# MSPM0G350X register map
Vendor: Texas Instruments; File version: This preliminary header file does not have a version number - build date: 2024-04-29 21:43:54
CPU: CM0 r0p1, little endian, MPU, no FPU, 3 interrupt priority bits
Registers are 32-bit, read-write, reset 0x0 unless marked. A register's access mark holds for its fields unless they carry their own. Offsets are from the block's base; [hi:lo] are bit positions; lines under a group give offsets from that group; {n}, {i} and the like mark numbered series; 'fields as' and 'values as' point back to an identical list; <NAME> marks a mode.

## CANFD0 (part 2 of 3) — PERIPHERALREGION
Base 0x40508000
{0x7200+0xA00*i} CANFD0_TI_WRAPPER[{i}] (i=0..0) group
  {0x0+0x410*j} CANFD0_PROCESSORS[{j}] (j=0..0) group
    {0x0+0x2C*k} CANFD0_MCANSS_REGS[{k}] (k=0..0) group
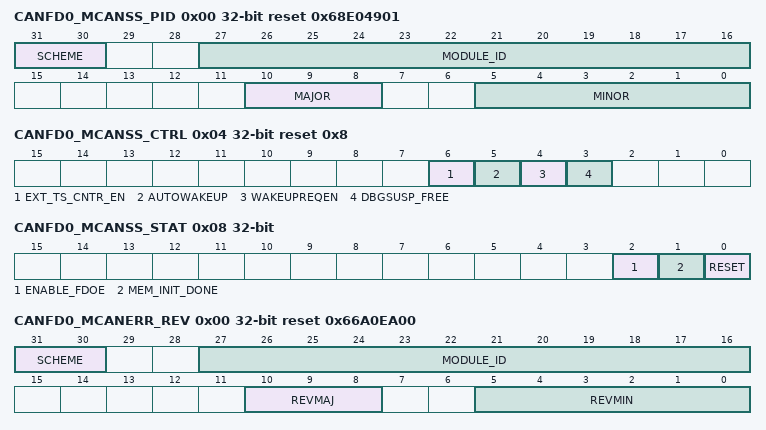
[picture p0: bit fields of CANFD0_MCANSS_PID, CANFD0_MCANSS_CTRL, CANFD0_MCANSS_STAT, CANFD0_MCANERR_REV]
      0x00 CANFD0_MCANSS_PID ro reset 0x68E04901 — MCAN Subsystem Revision Register
        [31:30] SCHEME — PID Register Scheme
        [27:16] MODULE_ID — Module Identification Number
        [10:8] MAJOR — Major Revision of the MCAN Subsystem
        [5:0] MINOR — Minor Revision of the MCAN Subsystem
      0x04 CANFD0_MCANSS_CTRL reset 0x8 — MCAN Subsystem Control Register
        [6] EXT_TS_CNTR_EN — External Timestamp Counter Enable. 0 External timestamp counter disabled 1 External timestamp counter enabled
        [5] AUTOWAKEUP — Automatic Wakeup Enable. Enables the MCANSS to automatically clear the MCAN CCCR.INIT bit, fully waking the MCAN up, on an enabled wakeup request. 0 Disable the automatic write to CCCR.INIT 1 Enable the automatic write to CCCR.INIT
        [4] WAKEUPREQEN — Wakeup Request Enable. Enables the MCANSS to wakeup on CAN RXD activity. 0 Disable wakeup request 1 Enables wakeup request
        [3] DBGSUSP_FREE — Debug Suspend Free Bit. Enables debug suspend. 0 Disable debug suspend 1 Enable debug suspend
      0x08 CANFD0_MCANSS_STAT ro (reset mask 0xFFFFFFFB) — MCAN Subsystem Status Register
        [2] ENABLE_FDOE — Flexible Datarate Operation Enable. Determines whether CAN FD operation may be enabled via the MCAN core CCCR.FDOE bit (bit 8) or if only standard CAN operation is possible with this instance of the MCAN. 0 MCAN is only capable of standard CAN communication 1 MCAN may be configured to perform CAN FD communication
        [1] MEM_INIT_DONE — Memory Initialization Done. 0 Message RAM initialization is in progress 1 Message RAM is initialized for use
        [0] RESET — Soft Reset Status. 0 Not in reset 1 Reset is in progress
      0x0C CANFD0_MCANSS_ICS — MCAN Subsystem Interrupt Clear Shadow Register
        [0] EXT_TS_CNTR_OVFL — External Timestamp Counter Overflow Interrupt Status Clear. Reads always return a 0. 0 Write of '0' has no effect 1 Write of '1' clears the MCANSS_IRS.EXT_TS_CNTR_OVFL bit
      0x10 CANFD0_MCANSS_IRS — MCAN Subsystem Interrupt Raw Satus Register
        [0] EXT_TS_CNTR_OVFL — External Timestamp Counter Overflow Interrupt Status. This bit is set by HW or by a SW write of '1'. To clear, use the MCANSS_ICS.EXT_TS_CNTR_OVFL bit. 0 External timestamp counter has not overflowed 1 External timestamp counter has overflowed When this bit is set to '1' by HW or SW, the MCANSS_EXT_TS_UNSERVICED_INTR_CNTR.EXT_TS_INTR_CNTR bit field will increment by 1.
      0x14 CANFD0_MCANSS_IECS — MCAN Subsystem Interrupt Enable Clear Shadow Register
        [0] EXT_TS_CNTR_OVFL — External Timestamp Counter Overflow Interrupt Enable Clear. Reads always return a 0. 0 Write of '0' has no effect 1 Write of '1' clears the MCANSS_IES.EXT_TS_CNTR_OVFL bit
      0x18 CANFD0_MCANSS_IE — MCAN Subsystem Interrupt Enable Register
        [0] EXT_TS_CNTR_OVFL — External Timestamp Counter Overflow Interrupt Enable. A write of '0' has no effect. A write of '1' sets the MCANSS_IES.EXT_TS_CNTR_OVFL bit.
      0x1C CANFD0_MCANSS_IES ro — MCAN Subsystem Interrupt Enable Status
        [0] EXT_TS_CNTR_OVFL — External Timestamp Counter Overflow Interrupt Enable Status. To set, use the CANSS_IE.EXT_TS_CNTR_OVFL bit. To clear, use the MCANSS_IECS.EXT_TS_CNTR_OVFL bit. 0 External timestamp counter overflow interrupt is not enabled 1 External timestamp counter overflow interrupt is enabled
      0x20 CANFD0_MCANSS_EOI — MCAN Subsystem End of Interrupt
        [7:0] EOI — End of Interrupt. A write to this register will clear the associated interrupt. If the unserviced interrupt counter is > 1, another interrupt is generated. 0x00 External TS Interrupt is cleared 0x01 MCAN(0) interrupt is cleared 0x02 MCAN(1) interrupt is cleared Other writes are ignored.
      0x24 CANFD0_MCANSS_EXT_TS_PRESCALER — MCAN Subsystem External Timestamp Prescaler 0
        [23:0] PRESCALER — External Timestamp Prescaler Reload Value. The external timestamp count rate is the host (system) clock rate divided by this value, except in the case of 0. A zero value in this bit field will act identically to a value of 0x000001.
      0x28 CANFD0_MCANSS_EXT_TS_UNSERVICED_INTR_CNTR ro — MCAN Subsystem External Timestamp Unserviced Interrupts Counter
        [4:0] EXT_TS_INTR_CNTR — External Timestamp Counter Unserviced Rollover Interrupts. If this value is > 1, an MCANSS_EOI write of '1' to bit 0 will issue another interrupt. The status of this bit field is affected by the MCANSS_IRS.EXT_TS_CNTR_OVFL bit field.
    {0x200+0x210*k} CANFD0_MCAN_ECC_REGS[{k}] (k=0..0) group
      0x00 CANFD0_MCANERR_REV ro reset 0x66A0EA00 — MCAN Error Aggregator Revision Register
        [31:30] SCHEME — PID Register Scheme
        [27:16] MODULE_ID — Module Identification Number
        [10:8] REVMAJ — Major Revision of the Error Aggregator
        [5:0] REVMIN — Minor Revision of the Error Aggregator
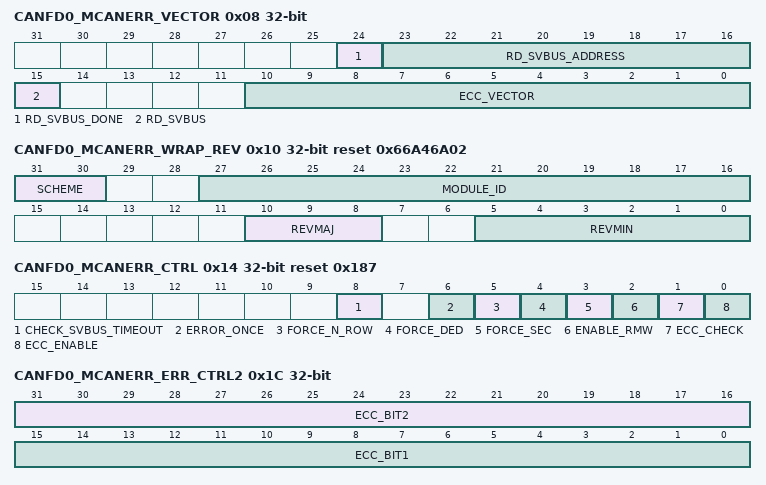
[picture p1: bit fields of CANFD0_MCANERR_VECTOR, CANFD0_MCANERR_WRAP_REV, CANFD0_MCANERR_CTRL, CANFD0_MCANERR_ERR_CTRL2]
      0x08 CANFD0_MCANERR_VECTOR — MCAN ECC Vector Register
        [24] RD_SVBUS_DONE ro — Read Completion Flag
        [23:16] RD_SVBUS_ADDRESS — Read Address Offset
        [15] RD_SVBUS — Read Trigger
        [10:0] ECC_VECTOR — ECC RAM ID. Each error detection and correction (EDC) controller has a bank of error registers (offsets 0x10 - 0x3B) associated with it. These registers are accessed via an internal serial bus (SVBUS). To access them through the ECC aggregator the controller ID desired must be written to the ECC_VECTOR field, together with the RD_SVBUS trigger and RD_SVBUS_ADDRESS bit field. This initiates the serial read which consummates by setting the RD_SVBUS_DONE bit. At this point the addressed register may be read by a normal CPU read of the appropriate offset address. 0x000 Message RAM ECC controller is selected Others Reserved (do not use) Subsequent writes through the SVBUS (offsets 0x10 - 0x3B) have a delayed completion. To avoid conflicts, perform a read back of a register within this range after writing.
      0x0C CANFD0_MCANERR_STAT ro reset 0x2 — MCAN Error Misc Status
        [10:0] NUM_RAMS — Number of RAMs. Number of ECC RAMs serviced by the aggregator.
      0x10 CANFD0_MCANERR_WRAP_REV ro reset 0x66A46A02 — MCAN ECC Wrapper Revision Register
        fields as CANFD0_TI_WRAPPER[0].CANFD0_PROCESSORS[0].CANFD0_MCAN_ECC_REGS[0].CANFD0_MCANERR_REV
      0x14 CANFD0_MCANERR_CTRL reset 0x187 — MCAN ECC Control
        [8] CHECK_SVBUS_TIMEOUT — Enables Serial VBUS timeout mechanism
        [6] ERROR_ONCE — If this bit is set, the FORCE_SEC/FORCE_DED will inject an error to the specified row only once. The FORCE_SEC bit will be cleared once a writeback happens. If writeback is not enabled, this error will be cleared the cycle following the read when the data is corrected. For double-bit errors, the FORCE_DED bit will be cleared the cycle following the double-bit error. Any subsequent reads will not force an error.
        [5] FORCE_N_ROW — Enable single/double-bit error on the next RAM read, regardless of the MCANERR_ERR_CTRL1.ECC_ROW setting. For write through mode, this applies to writes as well as reads.
        [4] FORCE_DED — Force double-bit error. Cleared the cycle following the error if ERROR_ONCE is asserted. For write through mode, this applies to writes as well as reads. MCANERR_ERR_CTRL1 and MCANERR_ERR_CTRL2 should be configured prior to setting this bit.
        [3] FORCE_SEC — Force single-bit error. Cleared on a writeback or the cycle following the error if ERROR_ONCE is asserted. For write through mode, this applies to writes as well as reads. MCANERR_ERR_CTRL1 and MCANERR_ERR_CTRL2 should be configured prior to setting this bit.
        [2] ENABLE_RMW — Enable read-modify-write on partial word writes
        [1] ECC_CHECK — Enable ECC Check. ECC is completely bypassed if both ECC_ENABLE and ECC_CHECK are '0'.
        [0] ECC_ENABLE — Enable ECC Generation
      0x18 CANFD0_MCANERR_ERR_CTRL1 — MCAN ECC Error Control 1 Register
      0x1C CANFD0_MCANERR_ERR_CTRL2 — MCAN ECC Error Control 2 Register
        [31:16] ECC_BIT2 — Second column/data bit that needs to be flipped when FORCE_DED is set
        [15:0] ECC_BIT1 — Column/Data bit that needs to be flipped when FORCE_SEC or FORCE_DED is set
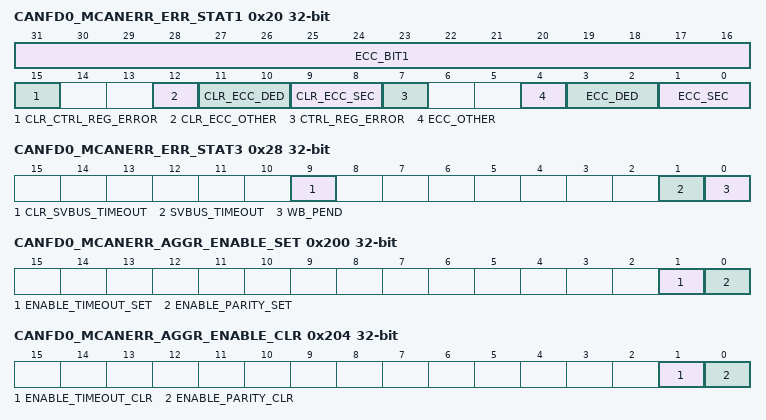
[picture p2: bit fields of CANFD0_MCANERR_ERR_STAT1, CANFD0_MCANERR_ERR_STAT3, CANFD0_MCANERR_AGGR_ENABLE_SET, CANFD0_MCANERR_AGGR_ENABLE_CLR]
      0x20 CANFD0_MCANERR_ERR_STAT1 — MCAN ECC Error Status 1 Register
        [31:16] ECC_BIT1 ro — ECC Error Bit Position. Indicates the bit position in the RAM data that is in error on an SEC error. Only valid on an SEC error. 0 Bit 0 is in error 1 Bit 1 is in error 2 Bit 2 is in error 3 Bit 3 is in error ... 31 Bit 31 is in error >32 Invalid
        [15] CLR_CTRL_REG_ERROR — Writing a '1' clears the CTRL_REG_ERROR bit
        [12] CLR_ECC_OTHER — Writing a '1' clears the ECC_OTHER bit.
        [11:10] CLR_ECC_DED — Clear ECC_DED. A write of a non-zero value to this bit field decrements the ECC_DED bit field by the value provided.
        [9:8] CLR_ECC_SEC — Clear ECC_SEC. A write of a non-zero value to this bit field decrements the ECC_SEC bit field by the value provided.
        [7] CTRL_REG_ERROR — Control Register Error. A bit field in the control register is in an ambiguous state. This means that the redundancy registers have detected a state where not all values are the same and has defaulted to the reset state. S/W needs to re-write these registers to a known state. A write of 1 will set this interrupt flag.
        [4] ECC_OTHER — SEC While Writeback Error Status 0 No SEC error while writeback pending 1 Indicates that successive single-bit errors have occurred while a writeback is still pending
        [3:2] ECC_DED — Double Bit Error Detected Status. A 2-bit saturating counter of the number of DED errors that have occurred since last cleared. 0 No double-bit error detected 1 One double-bit error was detected 2 Two double-bit errors were detected 3 Three double-bit errors were detected A write of a non-zero value to this bit field increments it by the value provided.
        [1:0] ECC_SEC — Single Bit Error Corrected Status. A 2-bit saturating counter of the number of SEC errors that have occurred since last cleared. 0 No single-bit error detected 1 One single-bit error was detected and corrected 2 Two single-bit errors were detected and corrected 3 Three single-bit errors were detected and corrected A write of a non-zero value to this bit field increments it by the value provided.
      0x24 CANFD0_MCANERR_ERR_STAT2 ro — MCAN ECC Error Status 2 Register
      0x28 CANFD0_MCANERR_ERR_STAT3 — MCAN ECC Error Status 3 Register
        [9] CLR_SVBUS_TIMEOUT — Write 1 to clear the Serial VBUS Timeout Flag
        [1] SVBUS_TIMEOUT — Serial VBUS Timeout Flag. Write 1 to set.
        [0] WB_PEND ro — Delayed Write Back Pending Status 0 No write back pending 1 An ECC data correction write back is pending
      0x3C CANFD0_MCANERR_SEC_EOI — MCAN Single Error Corrected End of Interrupt Register
        [0] EOI_WR — Write to this register indicates that software has acknowledged the pending interrupt and the next interrupt can be sent to the host. Note that a write to the MCANERR_ERR_STAT1.CLR_ECC_SEC goes through the SVBUS and has a delayed completion. To avoid an additional interrupt, read the MCANERR_ERR_STAT1 register back prior to writing to this bit field.
      0x40 CANFD0_MCANERR_SEC_STATUS — MCAN Single Error Corrected Interrupt Status Register
        [0] MSGMEM_PEND ro — Message RAM SEC Interrupt Pending 0 No SEC interrupt is pending 1 SEC interrupt is pending
      0x80 CANFD0_MCANERR_SEC_ENABLE_SET — MCAN Single Error Corrected Interrupt Enable Set Register
        [0] MSGMEM_ENABLE_SET — Message RAM SEC Interrupt Pending Enable Set. Writing a 1 to this bit enables the Message RAM SEC error interrupts. Writing a 0 has no effect. Reads return the corresponding enable bit's current value.
      0xC0 CANFD0_MCANERR_SEC_ENABLE_CLR — MCAN Single Error Corrected Interrupt Enable Clear Register
        [0] MSGMEM_ENABLE_CLR — Message RAM SEC Interrupt Pending Enable Clear. Writing a 1 to this bit disables the Message RAM SEC error interrupts. Writing a 0 has no effect. Reads return the corresponding enable bit's current value.
      0x13C CANFD0_MCANERR_DED_EOI — MCAN Double Error Detected End of Interrupt Register
        [0] EOI_WR — Write to this register indicates that software has acknowledged the pending interrupt and the next interrupt can be sent to the host. Note that a write to the MCANERR_ERR_STAT1.CLR_ECC_DED goes through the SVBUS and has a delayed completion. To avoid an additional interrupt, read the MCANERR_ERR_STAT1 register back prior to writing to this bit field.
      0x140 CANFD0_MCANERR_DED_STATUS — MCAN Double Error Detected Interrupt Status Register
        [0] MSGMEM_PEND ro — Message RAM DED Interrupt Pending 0 No DED interrupt is pending 1 DED interrupt is pending
      0x180 CANFD0_MCANERR_DED_ENABLE_SET — MCAN Double Error Detected Interrupt Enable Set Register
        [0] MSGMEM_ENABLE_SET — Message RAM DED Interrupt Pending Enable Set. Writing a 1 to this bit enables the Message RAM DED error interrupts. Writing a 0 has no effect. Reads return the corresponding enable bit's current value.
      0x1C0 CANFD0_MCANERR_DED_ENABLE_CLR — MCAN Double Error Detected Interrupt Enable Clear Register
        [0] MSGMEM_ENABLE_CLR — Message RAM DED Interrupt Pending Enable Clear. Writing a 1 to this bit disables the Message RAM DED error interrupts. Writing a 0 has no effect. Reads return the corresponding enable bit's current value.
      0x200 CANFD0_MCANERR_AGGR_ENABLE_SET — MCAN Error Aggregator Enable Set Register
        [1] ENABLE_TIMEOUT_SET — Write 1 to enable timeout errors. Reads return the corresponding enable bit's current value.
        [0] ENABLE_PARITY_SET — Write 1 to enable parity errors. Reads return the corresponding enable bit's current value.
      0x204 CANFD0_MCANERR_AGGR_ENABLE_CLR — MCAN Error Aggregator Enable Clear Register
        [1] ENABLE_TIMEOUT_CLR — Write 1 to disable timeout errors. Reads return the corresponding enable bit's current value.
        [0] ENABLE_PARITY_CLR — Write 1 to disable parity errors. Reads return the corresponding enable bit's current value.
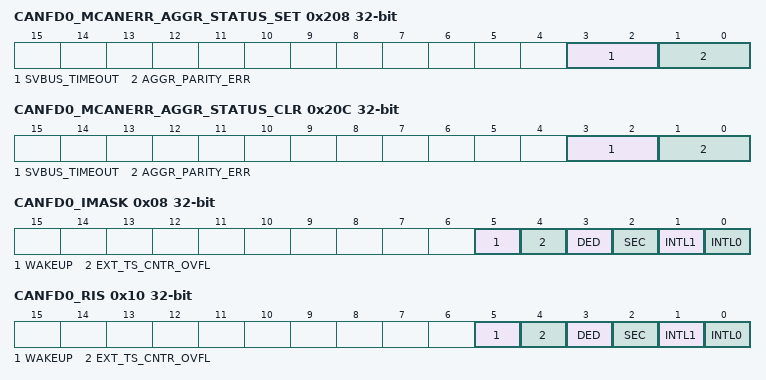
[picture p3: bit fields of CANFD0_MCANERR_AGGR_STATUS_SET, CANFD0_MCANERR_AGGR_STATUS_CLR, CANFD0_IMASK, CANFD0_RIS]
      0x208 CANFD0_MCANERR_AGGR_STATUS_SET — MCAN Error Aggregator Status Set Register
        [3:2] SVBUS_TIMEOUT — Aggregator Serial VBUS Timeout Error Status 2-bit saturating counter of the number of SVBUS timeout errors that have occurred since last cleared. 0 No timeout errors have occurred 1 One timeout error has occurred 2 Two timeout errors have occurred 3 Three timeout errors have occurred A write of a non-zero value to this bit field increments it by the value provided.
        [1:0] AGGR_PARITY_ERR — Aggregator Parity Error Status 2-bit saturating counter of the number of parity errors that have occurred since last cleared. 0 No parity errors have occurred 1 One parity error has occurred 2 Two parity errors have occurred 3 Three parity errors have occurred A write of a non-zero value to this bit field increments it by the value provided.
      0x20C CANFD0_MCANERR_AGGR_STATUS_CLR — MCAN Error Aggregator Status Clear Register
        [3:2] SVBUS_TIMEOUT — Aggregator Serial VBUS Timeout Error Status 2-bit saturating counter of the number of SVBUS timeout errors that have occurred since last cleared. 0 No timeout errors have occurred 1 One timeout error has occurred 2 Two timeout errors have occurred 3 Three timeout errors have occurred A write of a non-zero value to this bit field decrements it by the value provided.
        [1:0] AGGR_PARITY_ERR — Aggregator Parity Error Status 2-bit saturating counter of the number of parity errors that have occurred since last cleared. 0 No parity errors have occurred 1 One parity error has occurred 2 Two parity errors have occurred 3 Three parity errors have occurred A write of a non-zero value to this bit field decrements it by the value provided.
  {0x600+0x200*j} CANFD0_MSP[{j}] (j=0..0) group
    {0x20+0x2C*k} CANFD0_INT_EVENT0[{k}] (k=0..0) group
      0x00 CANFD0_IIDX ro — Interrupt Index Register
        [7:0] STAT — Interrupt index status
          0=NO_INTR (No interrupt pending.); 1=INTL0 (MCAN Interrupt Line 0 interrupt pending.); 2=INTL1 (MCAN Interrupt Line 1 interrupt pending.); 3=SEC (Message RAM SEC (Single Error Correction) interrupt pending.); 4=DED (Message RAM DED (Double Error Detection) interrupt pending.); 5=EXT_TS_CNTR_OVFL (External Timestamp Counter Overflow interrupt pending.); 6=WAKEUP (Clock Stop Wake Up interrupt pending.)
      0x08 CANFD0_IMASK — Interrupt mask
        [all] fields
          0=CLR (Clear Interrupt Mask); 1=SET (Set Interrrupt Mask)
        [5] WAKEUP — Clock Stop Wake Up interrupt mask.
        [4] EXT_TS_CNTR_OVFL — External Timestamp Counter Overflow interrupt mask.
        [3] DED — Massage RAM DED interrupt mask.
        [2] SEC — Message RAM SEC interrupt mask.
        [1] INTL1 — MCAN Interrupt Line 1 mask.
        [0] INTL0 — MCAN Interrupt Line 0 mask.
      0x10 CANFD0_RIS ro — Raw interrupt status
        [all] fields
          0=CLR (Interrupt did not occur); 1=SET (Interrupt occured)
        [5] WAKEUP — Clock Stop Wake Up interrupt.
        [4] EXT_TS_CNTR_OVFL — External Timestamp Counter Overflow interrupt.
        [3] DED — Message RAM DED interrupt.
        [2] SEC — Message RAM SEC interrupt.
        [1] INTL1 — MCAN Interrupt Line 1.
        [0] INTL0 — MCAN Interrupt Line 0.
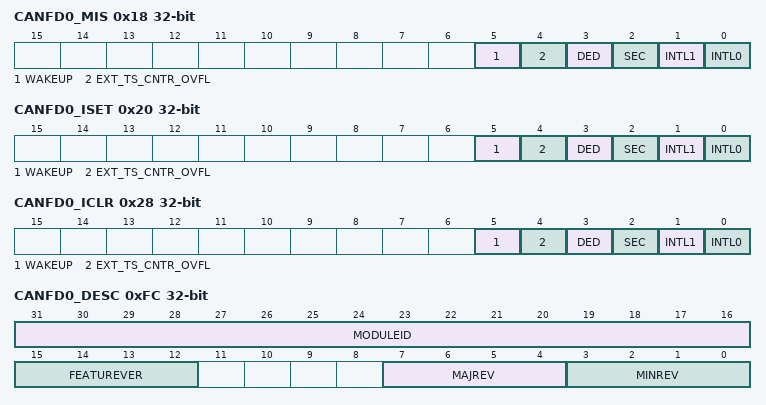
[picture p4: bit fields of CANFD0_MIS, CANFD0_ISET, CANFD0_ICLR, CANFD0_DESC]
      0x18 CANFD0_MIS ro — Masked interrupt status
        [all] fields
          0=CLR (Interrupt did not occur); 1=SET (Interrupt occured)
        [5] WAKEUP — Masked Clock Stop Wake Up interrupt.
        [4] EXT_TS_CNTR_OVFL — Masked External Timestamp Counter Overflow interrupt.
        [3] DED — Masked Message RAM DED interrupt.
        [2] SEC — Masked Message RAM SEC interrupt.
        [1] INTL1 — Masked MCAN Interrupt Line 1.
        [0] INTL0 — Masked MCAN Interrupt Line 0.
      0x20 CANFD0_ISET wo — Interrupt set
        [all] fields
          0=NO_EFFECT (Writing 0 has no effect); 1=SET (Set Interrupt)
        [5] WAKEUP — Set Clock Stop Wake Up interrupt.
        [4] EXT_TS_CNTR_OVFL — Set External Timestamp Counter Overflow interrupt.
        [3] DED — Set Message RAM DED interrupt.
        [2] SEC — Set Message RAM SEC interrupt.
        [1] INTL1 — Set MCAN Interrupt Line 1.
        [0] INTL0 — Set MCAN Interrupt Line 0.
      0x28 CANFD0_ICLR wo — Interrupt clear
        [all] fields
          0=NO_EFFECT (Writing 0 has no effect); 1=CLR (Clear Interrupt)
        [5] WAKEUP — Clear Clock Stop Wake Up interrupt.
        [4] EXT_TS_CNTR_OVFL — Clear External Timestamp Counter Overflow interrupt.
        [3] DED — Clear Message RAM DED interrupt.
        [2] SEC — Clear Message RAM SEC interrupt.
        [1] INTL1 — Clear MCAN Interrupt Line 1.
        [0] INTL0 — Clear MCAN Interrupt Line 0.
    0xE0 CANFD0_EVT_MODE — Event Mode
      [1:0] INT0_CFG ro — Event line mode select for event corresponding to [IPSTANDARD.INT_EVENT0]
        0=DISABLE (The interrupt or event line is disabled.); 1=SOFTWARE (The interrupt or event line is in software mode. Software must clear the RIS.); 2=HARDWARE (The interrupt or event line is in hardware mode. The hardware (another module) clears automatically the associated RIS flag.)
    0xFC CANFD0_DESC ro — Module Description
      [31:16] MODULEID — Module identification contains a unique peripheral identification number. The assignments are maintained in a central database for all of the platform modules to ensure uniqueness.
      [15:12] FEATUREVER — Feature Set for the module *instance*
        0=VERSION_0 (MCAN module with CAN-FD mode enabled <<Internal Note: This is an in-IP paper spin variant. How does this map to the SYS_MCAN_ENABLE_FD choice value?>>); 1=VERSION_1 (MCAN module with CAN-FD mode disabled <<Internal Note: This is an in-IP paper spin variant. How does this map to the SYS_MCAN_ENABLE_FD choice value?>>)
      [7:4] MAJREV — Major rev of the IP
      [3:0] MINREV — Minor rev of the IP
    0x100 CANFD0_MCANSS_CLKEN — MCAN module clock enable
      [0] CLK_REQEN — MCAN functional and MCAN/MCANSS MMR clock request enable bit
        0=CLR (MCAN module functional clock and Vbusp is not requested. These clocks are gated to the MCAN module.); 1=SET (Setting this bit requests MCAN module functional clock and Vbusp. These clocks are not gated to MCAN module.)
    0x104 CANFD0_MCANSS_CLKDIV — Clock divider
      [1:0] RATIO — Clock divide ratio specification. Enables configuring clock divide settings for the MCAN functional clock input to the MCAN-SS.
        0=DIV_BY_1_ (Divides input clock by 1); 1=DIV_BY_2_ (Divides input clock by 2); 2=DIV_BY_4_ (Divides input clock by 4)
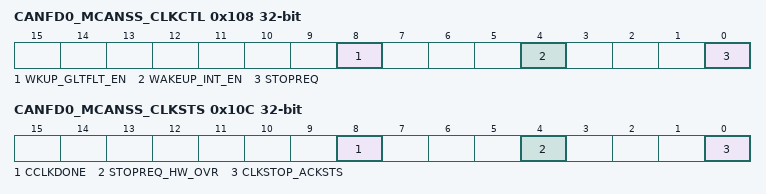
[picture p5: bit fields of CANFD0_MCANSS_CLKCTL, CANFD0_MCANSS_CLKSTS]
    0x108 CANFD0_MCANSS_CLKCTL — MCAN-SS clock stop control register
      [8] WKUP_GLTFLT_EN — Setting this bit enables the glitch filter on MCAN RXD input, which wakes up the MCAN controller to exit clock gating.
        0=DISABLE (Disable glitch filter enable on RXD input when MCAN is in clock stop mode (waiting for event on RXD input for clock stop wakeup).); 1=ENABLE (Enable glitch filter enable on RXD input when MCAN is in clock stop mode (waiting for event on RXD input for clock stop wakeup).)
      [4] WAKEUP_INT_EN — This bit contols enabling or disabling the MCAN IP clock stop wakeup interrupt (when MCANSS_CTRL.WAKEUPREQEN wakeup request is enabled to wakeup MCAN IP upon CAN RXD activity)
        0=DISABLE (Disable MCAN IP clock stop wakeup interrupt); 1=ENABLE (Enable MCAN IP clock stop wakeup interrupt)
      [0] STOPREQ — This bit is used to enable/disable MCAN clock (both host clock and functional clock) gating request. Note: This bit can be reset by HW by Clock-Stop Wake-up via CAN RX Activity. See spec for more details.
        0=DISABLE (Disable MCAN-SS clock stop request); 1=ENABLE (Enable MCAN-SS clock stop request)
    0x10C CANFD0_MCANSS_CLKSTS ro — MCANSS clock stop status register
      [8] CCLKDONE — This bit indicates the status of MCAN contoller clock request from GPRCM.
        0=RESET (MCAN controller clock is not available to the MCAN IP.); 1=SET (MCAN controller clock is enabled and available to the MCAN IP.)
      [4] STOPREQ_HW_OVR — MCANSS clock stop HW override status bit. This bit indicates when the MCANSS_CLKCTL.STOPREQ bit has been cleared by HW when a clock-stop wake-up event via CAN RX activity is trigged.
        0=RESET (MCANSS_CLKCTL.STOPREQ bit has not been cleared by HW.); 1=SET (MCANSS_CLKCTL.STOPREQ bit has been cleared by HW.)
      [0] CLKSTOP_ACKSTS — Clock stop acknowledge status from MCAN IP
        0=RESET (No clock stop acknowledged.); 1=SET (MCAN-SS may be clock gated by stopping both the CAN host and functional clocks.)

## Notices in the file
Copyright (C) 2024 Texas Instruments Incorporated - http://www.ti.com
Redistribution and use in source and binary forms, with or without
modification, are permitted provided that the following conditions
are met:
Redistributions of source code must retain the above copyright
notice, this list of conditions and the following disclaimer.
Redistributions in binary form must reproduce the above copyright
notice, this list of conditions and the following disclaimer in the
documentation and/or other materials provided with the
distribution.
Neither the name of Texas Instruments Incorporated nor the names of
its contributors may be used to endorse or promote products derived
from this software without specific prior written permission.
THIS SOFTWARE IS PROVIDED BY THE COPYRIGHT HOLDERS AND CONTRIBUTORS
"AS IS" AND ANY EXPRESS OR IMPLIED WARRANTIES, INCLUDING, BUT NOT
LIMITED TO, THE IMPLIED WARRANTIES OF MERCHANTABILITY AND FITNESS FOR
A PARTICULAR PURPOSE ARE DISCLAIMED. IN NO EVENT SHALL THE COPYRIGHT
OWNER OR CONTRIBUTORS BE LIABLE FOR ANY DIRECT, INDIRECT, INCIDENTAL,
SPECIAL, EXEMPLARY, OR CONSEQUENTIAL DAMAGES (INCLUDING, BUT NOT
LIMITED TO, PROCUREMENT OF SUBSTITUTE GOODS OR SERVICES; LOSS OF USE,
DATA, OR PROFITS; OR BUSINESS INTERRUPTION) HOWEVER CAUSED AND ON ANY
THEORY OF LIABILITY, WHETHER IN CONTRACT, STRICT LIABILITY, OR TORT
(INCLUDING NEGLIGENCE OR OTHERWISE) ARISING IN ANY WAY OUT OF THE USE
OF THIS SOFTWARE, EVEN IF ADVISED OF THE POSSIBILITY OF SUCH DAMAGE.
